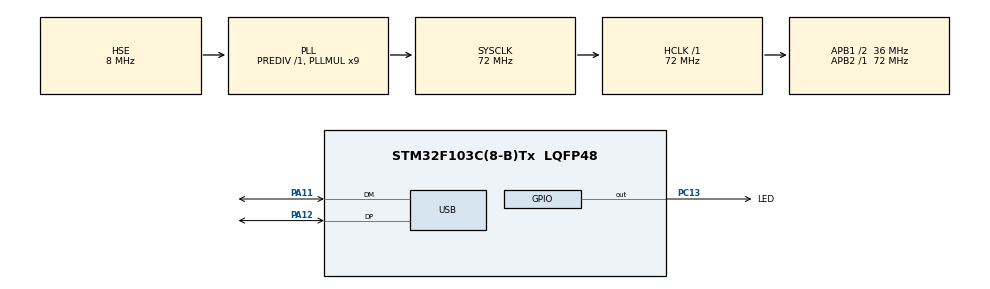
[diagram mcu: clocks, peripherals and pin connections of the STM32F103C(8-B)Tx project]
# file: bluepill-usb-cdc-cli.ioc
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FREERTOS.Tasks01=defaultTask,0,128,StartDefaultTask,Default,NULL,Dynamic,NULL,NULL;taskCliUsb,-3,128,StartTaskCliUsb,As external,NULL,Dynamic,NULL,NULL
FREERTOS.configUSE_NEWLIB_REENTRANT=1
Mcu.Family=STM32F1
Mcu.Name=STM32F103C(8-B)Tx
Mcu.Package=LQFP48
NVIC.PriorityGroup=NVIC_PRIORITYGROUP_4
NVIC.TIM1_UP_IRQn=true\:15\:0\:false\:false\:true\:false\:false\:true\:true
NVIC.TimeBase=TIM1_UP_IRQn
NVIC.TimeBaseIP=TIM1
NVIC.USB_LP_CAN1_RX0_IRQn=true\:5\:0\:false\:false\:true\:true\:false\:true\:true
PA11.Mode=Device
PA11.Signal=USB_DM
PA12.Mode=Device
PA12.Signal=USB_DP
PA13.Mode=Serial_Wire
PA13.Signal=SYS_JTMS-SWDIO
PA14.Mode=Serial_Wire
PA14.Signal=SYS_JTCK-SWCLK
PC13-TAMPER-RTC.GPIO_Label=LED
PC13-TAMPER-RTC.GPIO_PuPd=GPIO_PULLUP
PC13-TAMPER-RTC.PinState=GPIO_PIN_RESET
PC13-TAMPER-RTC.Signal=GPIO_Output
PD0-OSC_IN.Mode=HSE-External-Oscillator
PD0-OSC_IN.Signal=RCC_OSC_IN
PD1-OSC_OUT.Mode=HSE-External-Oscillator
PD1-OSC_OUT.Signal=RCC_OSC_OUT
ProjectManager.HeapSize=0x200
ProjectManager.StackSize=0x400
ProjectManager.TargetToolchain=STM32CubeIDE
RCC.AHBFreq_Value=72000000
RCC.APB1CLKDivider=RCC_HCLK_DIV2
RCC.APB1Freq_Value=36000000
RCC.APB1TimFreq_Value=72000000
RCC.APB2Freq_Value=72000000
RCC.APB2TimFreq_Value=72000000
RCC.HCLKFreq_Value=72000000
RCC.PLLMUL=RCC_PLL_MUL9
RCC.PLLSourceVirtual=RCC_PLLSOURCE_HSE
RCC.SYSCLKFreq_VALUE=72000000
RCC.SYSCLKSource=RCC_SYSCLKSOURCE_PLLCLK
RCC.USBFreq_Value=48000000
RCC.USBPrescaler=RCC_USBCLKSOURCE_PLL_DIV1_5
USB_DEVICE.CLASS_NAME_FS=CDC
USB_DEVICE.PRODUCT_STRING_CDC_FS=Test Product
USB_DEVICE.VirtualMode=Cdc
USB_DEVICE.VirtualModeFS=Cdc_FS
VP_FREERTOS_VS_CMSIS_V1.Mode=CMSIS_V1
VP_SYS_VS_tim1.Mode=TIM1
VP_USB_DEVICE_VS_USB_DEVICE_CDC_FS.Mode=CDC_FS
board=custom

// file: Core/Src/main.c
/* USER CODE BEGIN Header */
/**
  ******************************************************************************
  * @file           : main.c
  * @brief          : Main program body
  ******************************************************************************
  * @attention
  *
  * <h2><center>&copy; Copyright (c) 2021 STMicroelectronics.
  * All rights reserved.</center></h2>
  *
  * This software component is licensed by ST under BSD 3-Clause license,
  * the "License"; You may not use this file except in compliance with the
  * License. You may obtain a copy of the License at:
  *                        opensource.org/licenses/BSD-3-Clause
  *
  ******************************************************************************
  */
/* USER CODE END Header */
#include "main.h"
#include "cmsis_os.h"
#include "usb_device.h"

/* USER CODE BEGIN Includes */
#include "usbd_cdc_if.h"
#include "taskCliUsb.h"
/* USER CODE END Includes */

osThreadId defaultTaskHandle;
osThreadId taskCliUsbHandle;

void SystemClock_Config(void);
static void MX_GPIO_Init(void);
void StartDefaultTask(void const * argument);
extern void StartTaskCliUsb(void const * argument);

int main(void)
{

  /* MCU Configuration--------------------------------------------------------*/

  /* Reset of all peripherals, Initializes the Flash interface and the Systick. */
  HAL_Init();

  /* Configure the system clock */
  SystemClock_Config();

  /* Initialize all configured peripherals */
  MX_GPIO_Init();
  /* USER CODE BEGIN 2 */

  // Read buffer
  uint8_t rxData[8];
  memset(rxData, 0, 8);

  // Flash LED briefly on reset
  HAL_GPIO_WritePin(LED_GPIO_Port, LED_Pin, GPIO_PIN_RESET);
  HAL_Delay(500);
  HAL_GPIO_WritePin(LED_GPIO_Port, LED_Pin, GPIO_PIN_SET);

  /* USER CODE END 2 */

  /* Create the thread(s) */
  /* definition and creation of defaultTask */
  osThreadDef(defaultTask, StartDefaultTask, osPriorityNormal, 0, 128);
  defaultTaskHandle = osThreadCreate(osThread(defaultTask), NULL);

  /* definition and creation of taskCliUsb */
  osThreadDef(taskCliUsb, StartTaskCliUsb, osPriorityIdle, 0, 128);
  taskCliUsbHandle = osThreadCreate(osThread(taskCliUsb), NULL);

  /* Start scheduler */
  osKernelStart();

  /* We should never get here as control is now taken by the scheduler */
  /* Infinite loop */
  while (1)
  {

    /* USER CODE BEGIN 3 */

    // Echo data
    uint16_t bytesAvailable = CDC_GetRxBufferBytesAvailable_FS();
    if (bytesAvailable > 0) {
    	uint16_t bytesToRead = bytesAvailable >= 8 ? 8 : bytesAvailable;
    	if (CDC_ReadRxBuffer_FS(rxData, bytesToRead) == USB_CDC_RX_BUFFER_OK) {
            while (CDC_Transmit_FS(rxData, bytesToRead) == USBD_BUSY);
    	}
    }

  }
  /* USER CODE END 3 */
}

void SystemClock_Config(void)
{
  RCC_OscInitTypeDef RCC_OscInitStruct = {0};
  RCC_ClkInitTypeDef RCC_ClkInitStruct = {0};
  RCC_PeriphCLKInitTypeDef PeriphClkInit = {0};

  /** Initializes the RCC Oscillators according to the specified parameters
  * in the RCC_OscInitTypeDef structure.
  */
  RCC_OscInitStruct.OscillatorType = RCC_OSCILLATORTYPE_HSE;
  RCC_OscInitStruct.HSEState = RCC_HSE_ON;
  RCC_OscInitStruct.HSEPredivValue = RCC_HSE_PREDIV_DIV1;
  RCC_OscInitStruct.HSIState = RCC_HSI_ON;
  RCC_OscInitStruct.PLL.PLLState = RCC_PLL_ON;
  RCC_OscInitStruct.PLL.PLLSource = RCC_PLLSOURCE_HSE;
  RCC_OscInitStruct.PLL.PLLMUL = RCC_PLL_MUL9;
  if (HAL_RCC_OscConfig(&RCC_OscInitStruct) != HAL_OK)
  {
    Error_Handler();
  }

  /** Initializes the CPU, AHB and APB buses clocks
  */
  RCC_ClkInitStruct.ClockType = RCC_CLOCKTYPE_HCLK|RCC_CLOCKTYPE_SYSCLK
                              |RCC_CLOCKTYPE_PCLK1|RCC_CLOCKTYPE_PCLK2;
  RCC_ClkInitStruct.SYSCLKSource = RCC_SYSCLKSOURCE_PLLCLK;
  RCC_ClkInitStruct.AHBCLKDivider = RCC_SYSCLK_DIV1;
  RCC_ClkInitStruct.APB1CLKDivider = RCC_HCLK_DIV2;
  RCC_ClkInitStruct.APB2CLKDivider = RCC_HCLK_DIV1;

  if (HAL_RCC_ClockConfig(&RCC_ClkInitStruct, FLASH_LATENCY_2) != HAL_OK)
  {
    Error_Handler();
  }
  PeriphClkInit.PeriphClockSelection = RCC_PERIPHCLK_USB;
  PeriphClkInit.UsbClockSelection = RCC_USBCLKSOURCE_PLL_DIV1_5;
  if (HAL_RCCEx_PeriphCLKConfig(&PeriphClkInit) != HAL_OK)
  {
    Error_Handler();
  }
}

static void MX_GPIO_Init(void)
{
  GPIO_InitTypeDef GPIO_InitStruct = {0};

  /* GPIO Ports Clock Enable */
  __HAL_RCC_GPIOC_CLK_ENABLE();
  __HAL_RCC_GPIOD_CLK_ENABLE();
  __HAL_RCC_GPIOA_CLK_ENABLE();

  /*Configure GPIO pin Output Level */
  HAL_GPIO_WritePin(LED_GPIO_Port, LED_Pin, GPIO_PIN_RESET);

  /*Configure GPIO pin : LED_Pin */
  GPIO_InitStruct.Pin = LED_Pin;
  GPIO_InitStruct.Mode = GPIO_MODE_OUTPUT_PP;
  GPIO_InitStruct.Pull = GPIO_PULLUP;
  GPIO_InitStruct.Speed = GPIO_SPEED_FREQ_LOW;
  HAL_GPIO_Init(LED_GPIO_Port, &GPIO_InitStruct);

}

void StartDefaultTask(void const * argument)
{
  /* init code for USB_DEVICE */
  MX_USB_DEVICE_Init();
  for(;;)
  {
    osDelay(1);
  }
}

void HAL_TIM_PeriodElapsedCallback(TIM_HandleTypeDef *htim)
{
  if (htim->Instance == TIM1) {
    HAL_IncTick();
  }
}

void Error_Handler(void)
{
  __disable_irq();
  while (1)
  {
  }
}
